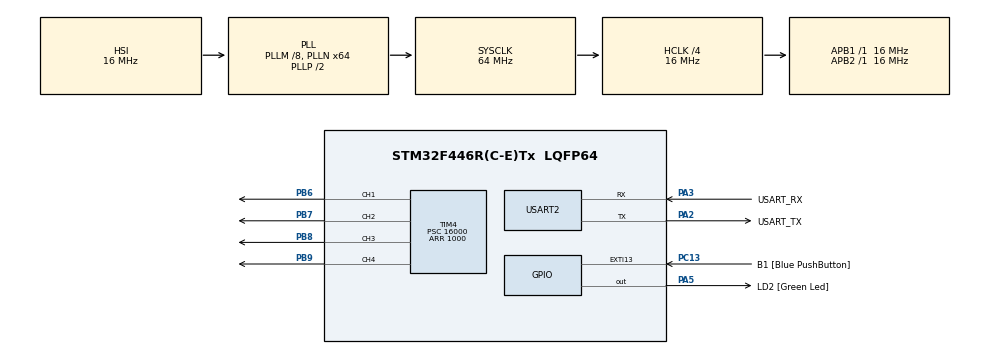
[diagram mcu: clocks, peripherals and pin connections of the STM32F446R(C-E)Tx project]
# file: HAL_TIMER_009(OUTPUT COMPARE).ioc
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Mcu.Family=STM32F4
Mcu.Name=STM32F446R(C-E)Tx
Mcu.Package=LQFP64
NVIC.PriorityGroup=NVIC_PRIORITYGROUP_0
PA13.GPIO_Label=TMS
PA13.Mode=Serial_Wire
PA13.Signal=SYS_JTMS-SWDIO
PA14.GPIO_Label=TCK
PA14.Mode=Serial_Wire
PA14.Signal=SYS_JTCK-SWCLK
PA2.GPIO_Label=USART_TX
PA2.Mode=Asynchronous
PA2.Signal=USART2_TX
PA3.GPIO_Label=USART_RX
PA3.Mode=Asynchronous
PA3.Signal=USART2_RX
PA5.GPIO_Label=LD2 [Green Led]
PA5.Signal=GPIO_Output
PB3.GPIO_Label=SWO
PB3.Signal=SYS_JTDO-SWO
PB6.Signal=S_TIM4_CH1
PB7.Signal=S_TIM4_CH2
PB8.Signal=S_TIM4_CH3
PB9.Signal=S_TIM4_CH4
PC13.GPIO_Label=B1 [Blue PushButton]
PC13.GPIO_ModeDefaultEXTI=GPIO_MODE_IT_FALLING
PC13.Signal=GPXTI13
PC14-OSC32_IN.Mode=LSE-External-Oscillator
PC14-OSC32_IN.Signal=RCC_OSC32_IN
PC15-OSC32_OUT.Mode=LSE-External-Oscillator
PC15-OSC32_OUT.Signal=RCC_OSC32_OUT
PH0-OSC_IN.Mode=HSE-External-Oscillator
PH0-OSC_IN.Signal=RCC_OSC_IN
PH1-OSC_OUT.Mode=HSE-External-Oscillator
PH1-OSC_OUT.Signal=RCC_OSC_OUT
ProjectManager.HeapSize=0x200
ProjectManager.StackSize=0x400
ProjectManager.TargetToolchain=MDK-ARM V5.27
RCC.48MHZClocksFreq_Value=84000000
RCC.AHBCLKDivider=RCC_SYSCLK_DIV4
RCC.AHBFreq_Value=16000000
RCC.APB1Freq_Value=16000000
RCC.APB1TimFreq_Value=16000000
RCC.APB2Freq_Value=16000000
RCC.APB2TimFreq_Value=16000000
RCC.CortexFreq_Value=16000000
RCC.FLatency-AdvancedSettings=FLASH_LATENCY_0
RCC.HCLKFreq_Value=16000000
RCC.HSE_VALUE=8000000
RCC.HSI_VALUE=16000000
RCC.PLLM=8
RCC.PLLN=64
RCC.SYSCLKFreq_VALUE=64000000
RCC.SYSCLKSource=RCC_SYSCLKSOURCE_PLLCLK
RCC.USBFreq_Value=64000000
RCC.VCOOutputFreq_Value=128000000
SH.S_TIM4_CH1.0=TIM4_CH1,Output Compare1 CH1
SH.S_TIM4_CH2.0=TIM4_CH2,Output Compare2 CH2
SH.S_TIM4_CH3.0=TIM4_CH3,Output Compare3 CH3
SH.S_TIM4_CH4.0=TIM4_CH4,Output Compare4 CH4
TIM4.Channel-Output\ Compare1\ CH1=TIM_CHANNEL_1
TIM4.Channel-Output\ Compare2\ CH2=TIM_CHANNEL_2
TIM4.Channel-Output\ Compare3\ CH3=TIM_CHANNEL_3
TIM4.Channel-Output\ Compare4\ CH4=TIM_CHANNEL_4
TIM4.OCMode_1=TIM_OCMODE_TOGGLE
TIM4.OCMode_2=TIM_OCMODE_TOGGLE
TIM4.OCMode_3=TIM_OCMODE_TOGGLE
TIM4.OCMode_4=TIM_OCMODE_TOGGLE
TIM4.Period=1000
TIM4.Prescaler=16000
TIM4.Pulse-Output\ Compare1\ CH1=250
TIM4.Pulse-Output\ Compare2\ CH2=500
TIM4.Pulse-Output\ Compare3\ CH3=750
TIM4.Pulse-Output\ Compare4\ CH4=1000
USART2.VirtualMode=VM_ASYNC
VP_TIM4_VS_ClockSourceINT.Mode=Internal
board=NUCLEO-F446RE

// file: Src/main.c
/* USER CODE BEGIN Header */
/**
  ******************************************************************************
  * @file           : main.c
  * @brief          : Main program body
  ******************************************************************************
  * @attention
  *
  * <h2><center>&copy; Copyright (c) 2020 STMicroelectronics.
  * All rights reserved.</center></h2>
  *
  * This software component is licensed by ST under BSD 3-Clause license,
  * the "License"; You may not use this file except in compliance with the
  * License. You may obtain a copy of the License at:
  *                        opensource.org/licenses/BSD-3-Clause
  *
  ******************************************************************************
  */
/* USER CODE END Header */

#include "main.h"

TIM_HandleTypeDef htim4;

UART_HandleTypeDef huart2;

void SystemClock_Config(void);
static void MX_GPIO_Init(void);
static void MX_USART2_UART_Init(void);
static void MX_TIM4_Init(void);

int main(void)
{

  /* MCU Configuration--------------------------------------------------------*/

  /* Reset of all peripherals, Initializes the Flash interface and the Systick. */
  HAL_Init();

  /* Configure the system clock */
  SystemClock_Config();

  /* Initialize all configured peripherals */
  MX_GPIO_Init();
  MX_USART2_UART_Init();
  MX_TIM4_Init();
  /* USER CODE BEGIN 2 */
	HAL_TIM_OC_Start(&htim4,TIM_CHANNEL_1);			//	Whole timer channels activated
	HAL_TIM_OC_Start(&htim4,TIM_CHANNEL_2);			// 	All events have done in cubemx check timer functions for learn
	HAL_TIM_OC_Start(&htim4,TIM_CHANNEL_3);
	HAL_TIM_OC_Start(&htim4,TIM_CHANNEL_4);

  /* USER CODE END 2 */

  /* Infinite loop */
  while (1)
  {

  }
}

void SystemClock_Config(void)
{
  RCC_OscInitTypeDef RCC_OscInitStruct = {0};
  RCC_ClkInitTypeDef RCC_ClkInitStruct = {0};

  /** Configure the main internal regulator output voltage
  */
  __HAL_RCC_PWR_CLK_ENABLE();
  __HAL_PWR_VOLTAGESCALING_CONFIG(PWR_REGULATOR_VOLTAGE_SCALE3);
  /** Initializes the CPU, AHB and APB busses clocks
  */
  RCC_OscInitStruct.OscillatorType = RCC_OSCILLATORTYPE_HSI;
  RCC_OscInitStruct.HSIState = RCC_HSI_ON;
  RCC_OscInitStruct.HSICalibrationValue = RCC_HSICALIBRATION_DEFAULT;
  RCC_OscInitStruct.PLL.PLLState = RCC_PLL_ON;
  RCC_OscInitStruct.PLL.PLLSource = RCC_PLLSOURCE_HSI;
  RCC_OscInitStruct.PLL.PLLM = 8;
  RCC_OscInitStruct.PLL.PLLN = 64;
  RCC_OscInitStruct.PLL.PLLP = RCC_PLLP_DIV2;
  RCC_OscInitStruct.PLL.PLLQ = 2;
  RCC_OscInitStruct.PLL.PLLR = 2;
  if (HAL_RCC_OscConfig(&RCC_OscInitStruct) != HAL_OK)
  {
    Error_Handler();
  }
  /** Initializes the CPU, AHB and APB busses clocks
  */
  RCC_ClkInitStruct.ClockType = RCC_CLOCKTYPE_HCLK|RCC_CLOCKTYPE_SYSCLK
                              |RCC_CLOCKTYPE_PCLK1|RCC_CLOCKTYPE_PCLK2;
  RCC_ClkInitStruct.SYSCLKSource = RCC_SYSCLKSOURCE_PLLCLK;
  RCC_ClkInitStruct.AHBCLKDivider = RCC_SYSCLK_DIV4;
  RCC_ClkInitStruct.APB1CLKDivider = RCC_HCLK_DIV1;
  RCC_ClkInitStruct.APB2CLKDivider = RCC_HCLK_DIV1;

  if (HAL_RCC_ClockConfig(&RCC_ClkInitStruct, FLASH_LATENCY_0) != HAL_OK)
  {
    Error_Handler();
  }
}

static void MX_TIM4_Init(void)
{

  TIM_ClockConfigTypeDef sClockSourceConfig = {0};
  TIM_MasterConfigTypeDef sMasterConfig = {0};
  TIM_OC_InitTypeDef sConfigOC = {0};

  htim4.Instance = TIM4;
  htim4.Init.Prescaler = 16000;
  htim4.Init.CounterMode = TIM_COUNTERMODE_UP;
  htim4.Init.Period = 1000;
  htim4.Init.ClockDivision = TIM_CLOCKDIVISION_DIV1;
  htim4.Init.AutoReloadPreload = TIM_AUTORELOAD_PRELOAD_DISABLE;
  if (HAL_TIM_Base_Init(&htim4) != HAL_OK)
  {
    Error_Handler();
  }
  sClockSourceConfig.ClockSource = TIM_CLOCKSOURCE_INTERNAL;
  if (HAL_TIM_ConfigClockSource(&htim4, &sClockSourceConfig) != HAL_OK)
  {
    Error_Handler();
  }
  if (HAL_TIM_OC_Init(&htim4) != HAL_OK)
  {
    Error_Handler();
  }
  sMasterConfig.MasterOutputTrigger = TIM_TRGO_RESET;
  sMasterConfig.MasterSlaveMode = TIM_MASTERSLAVEMODE_DISABLE;
  if (HAL_TIMEx_MasterConfigSynchronization(&htim4, &sMasterConfig) != HAL_OK)
  {
    Error_Handler();
  }
  sConfigOC.OCMode = TIM_OCMODE_TOGGLE;
  sConfigOC.Pulse = 250;
  sConfigOC.OCPolarity = TIM_OCPOLARITY_HIGH;
  sConfigOC.OCFastMode = TIM_OCFAST_DISABLE;
  if (HAL_TIM_OC_ConfigChannel(&htim4, &sConfigOC, TIM_CHANNEL_1) != HAL_OK)
  {
    Error_Handler();
  }
  sConfigOC.Pulse = 500;
  if (HAL_TIM_OC_ConfigChannel(&htim4, &sConfigOC, TIM_CHANNEL_2) != HAL_OK)
  {
    Error_Handler();
  }
  sConfigOC.Pulse = 750;
  if (HAL_TIM_OC_ConfigChannel(&htim4, &sConfigOC, TIM_CHANNEL_3) != HAL_OK)
  {
    Error_Handler();
  }
  sConfigOC.Pulse = 1000;
  if (HAL_TIM_OC_ConfigChannel(&htim4, &sConfigOC, TIM_CHANNEL_4) != HAL_OK)
  {
    Error_Handler();
  }
  HAL_TIM_MspPostInit(&htim4);

}

static void MX_USART2_UART_Init(void)
{

  huart2.Instance = USART2;
  huart2.Init.BaudRate = 115200;
  huart2.Init.WordLength = UART_WORDLENGTH_8B;
  huart2.Init.StopBits = UART_STOPBITS_1;
  huart2.Init.Parity = UART_PARITY_NONE;
  huart2.Init.Mode = UART_MODE_TX_RX;
  huart2.Init.HwFlowCtl = UART_HWCONTROL_NONE;
  huart2.Init.OverSampling = UART_OVERSAMPLING_16;
  if (HAL_UART_Init(&huart2) != HAL_OK)
  {
    Error_Handler();
  }

}

static void MX_GPIO_Init(void)
{
  GPIO_InitTypeDef GPIO_InitStruct = {0};

  /* GPIO Ports Clock Enable */
  __HAL_RCC_GPIOC_CLK_ENABLE();
  __HAL_RCC_GPIOH_CLK_ENABLE();
  __HAL_RCC_GPIOA_CLK_ENABLE();
  __HAL_RCC_GPIOB_CLK_ENABLE();

  /*Configure GPIO pin Output Level */
  HAL_GPIO_WritePin(LD2_GPIO_Port, LD2_Pin, GPIO_PIN_RESET);

  /*Configure GPIO pin : B1_Pin */
  GPIO_InitStruct.Pin = B1_Pin;
  GPIO_InitStruct.Mode = GPIO_MODE_IT_FALLING;
  GPIO_InitStruct.Pull = GPIO_NOPULL;
  HAL_GPIO_Init(B1_GPIO_Port, &GPIO_InitStruct);

  /*Configure GPIO pin : LD2_Pin */
  GPIO_InitStruct.Pin = LD2_Pin;
  GPIO_InitStruct.Mode = GPIO_MODE_OUTPUT_PP;
  GPIO_InitStruct.Pull = GPIO_NOPULL;
  GPIO_InitStruct.Speed = GPIO_SPEED_FREQ_LOW;
  HAL_GPIO_Init(LD2_GPIO_Port, &GPIO_InitStruct);

}

void Error_Handler(void)
{
}

/************************ (C) COPYRIGHT STMicroelectronics *****END OF FILE****/
